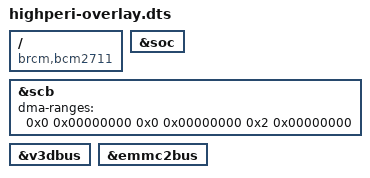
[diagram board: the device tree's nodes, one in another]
/*
 * highperi.dts
 */

/dts-v1/;
/plugin/;

/ {
	compatible = "brcm,bcm2711";

	fragment@0 {
		target = <&soc>;
		#address-cells = <2>;
		#size-cells = <1>;

		__overlay__ {
			#address-cells = <1>;
			#size-cells = <1>;
			ranges = <0x7c000000  0x4 0x7c000000  0x04000000>,
				 <0x40000000  0x4 0xc0000000  0x00800000>;
		};
	};

	fragment@1 {
		target = <&scb>;
		#address-cells = <2>;
		#size-cells = <1>;

		__overlay__ {
			#address-cells = <2>;
			#size-cells = <2>;
			ranges = <0x0 0x7c000000  0x4 0x7c000000  0x0 0x04000000>,
				 <0x0 0x40000000  0x4 0xc0000000  0x0 0x00800000>,
				 <0x6 0x00000000  0x6 0x00000000  0x0 0x40000000>;
			dma-ranges = <0x0 0x00000000  0x0 0x00000000  0x2 0x00000000>;
		};
	};

	fragment@2 {
		target = <&v3dbus>;
		#address-cells = <2>;
		#size-cells = <1>;

		__overlay__ {
			#address-cells = <1>;
			#size-cells = <2>;
			ranges = <0x7c500000  0x4 0x7c500000  0x0 0x03300000>,
				 <0x40000000  0x4 0xc0000000  0x0 0x00800000>;
		};
	};

	fragment@3 {
		target = <&emmc2bus>;
		#address-cells = <2>;
		#size-cells = <1>;

		__overlay__ {
			#address-cells = <2>;
			#size-cells = <1>;
			ranges = <0x0 0x7e000000  0x4 0x7e000000  0x01800000>;
		};
	};
};
